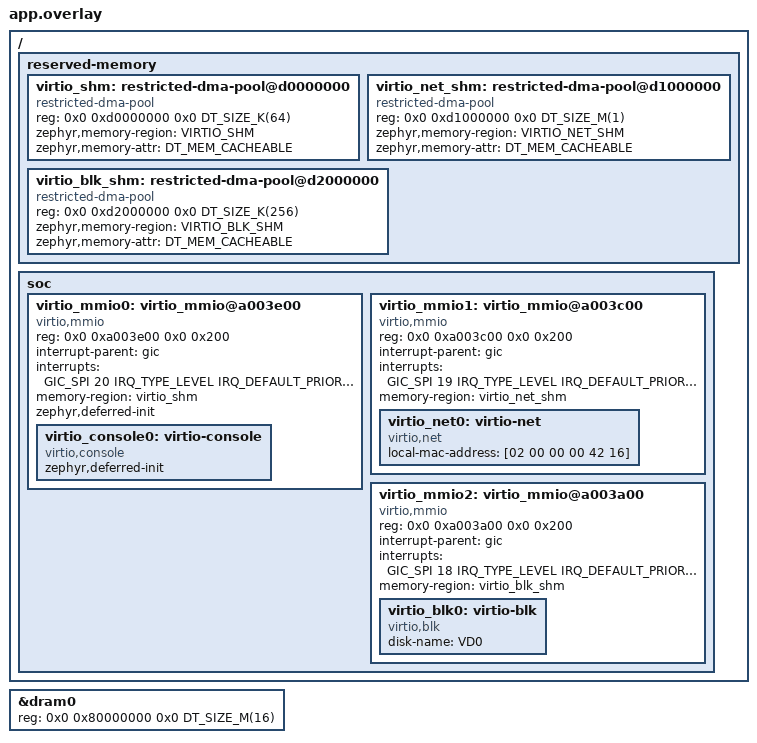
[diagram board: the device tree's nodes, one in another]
/*
 * SPDX-License-Identifier: Apache-2.0
 *
 * Memory layout and Remote I/O (VirtIO) device of the Zephyr VM, matching the
 * Bao configuration in configs/<platform>.c.
 */

#include <zephyr/dt-bindings/interrupt-controller/arm-gic.h>
#include <zephyr/dt-bindings/memory-attr/memory-attr.h>

/* Private VM memory: Zephyr's image and all of its RAM live here */
&dram0 {
	reg = <0x0 0x80000000 0x0 DT_SIZE_M(16)>;
};

/ {
	/*
	 * The only memory shared with the VirtIO backend VM, declared as
	 * restricted DMA pools: the VirtIO transport allocates the virtqueues
	 * of a device from its pool and bounces the driver buffers through
	 * it, so nothing else of Zephyr is visible to the backend. Bao shares
	 * one region per Remote I/O device, so each device has its own pool.
	 * The zephyr,memory-attr property is what gets a region mapped by the
	 * MMU.
	 */
	reserved-memory {
		#address-cells = <2>;
		#size-cells = <2>;
		ranges;

		virtio_shm: restricted-dma-pool@d0000000 {
			compatible = "restricted-dma-pool", "zephyr,memory-region";
			reg = <0x0 0xd0000000 0x0 DT_SIZE_K(64)>;
			zephyr,memory-region = "VIRTIO_SHM";
			zephyr,memory-attr = <DT_MEM_CACHEABLE>;
		};

		virtio_net_shm: restricted-dma-pool@d1000000 {
			compatible = "restricted-dma-pool", "zephyr,memory-region";
			reg = <0x0 0xd1000000 0x0 DT_SIZE_M(1)>;
			zephyr,memory-region = "VIRTIO_NET_SHM";
			zephyr,memory-attr = <DT_MEM_CACHEABLE>;
		};

		virtio_blk_shm: restricted-dma-pool@d2000000 {
			compatible = "restricted-dma-pool", "zephyr,memory-region";
			reg = <0x0 0xd2000000 0x0 DT_SIZE_K(256)>;
			zephyr,memory-region = "VIRTIO_BLK_SHM";
			zephyr,memory-attr = <DT_MEM_CACHEABLE>;
		};
	};

	soc {
		/*
		 * VirtIO MMIO device emulated by the backend. Accesses are
		 * forwarded by Bao to the backend, so the initialization is
		 * deferred until the application decides to wait for it. The
		 * interrupt (SPI 20, i.e. interrupt 52) is injected by Bao.
		 */
		virtio_mmio0: virtio_mmio@a003e00 {
			compatible = "virtio,mmio";
			reg = <0x0 0xa003e00 0x0 0x200>;
			interrupt-parent = <&gic>;
			interrupts = <GIC_SPI 20 IRQ_TYPE_LEVEL IRQ_DEFAULT_PRIORITY>;
			memory-region = <&virtio_shm>;
			zephyr,deferred-init;
			status = "okay";

			virtio_console0: virtio-console {
				compatible = "virtio,console";
				zephyr,deferred-init;
				status = "okay";
			};
		};

		/*
		 * VirtIO network device (SPI 19, i.e. interrupt 51). The
		 * network stack sets its interface up at boot, so this one is
		 * not deferred: Zephyr only boots once the backend is running.
		 */
		virtio_mmio1: virtio_mmio@a003c00 {
			compatible = "virtio,mmio";
			reg = <0x0 0xa003c00 0x0 0x200>;
			interrupt-parent = <&gic>;
			interrupts = <GIC_SPI 19 IRQ_TYPE_LEVEL IRQ_DEFAULT_PRIORITY>;
			memory-region = <&virtio_net_shm>;
			status = "okay";

			virtio_net0: virtio-net {
				compatible = "virtio,net";
				local-mac-address = [02 00 00 00 42 16];
				status = "okay";
			};
		};

		/*
		 * VirtIO block device (SPI 18, i.e. interrupt 50), also set
		 * up at boot.
		 */
		virtio_mmio2: virtio_mmio@a003a00 {
			compatible = "virtio,mmio";
			reg = <0x0 0xa003a00 0x0 0x200>;
			interrupt-parent = <&gic>;
			interrupts = <GIC_SPI 18 IRQ_TYPE_LEVEL IRQ_DEFAULT_PRIORITY>;
			memory-region = <&virtio_blk_shm>;
			status = "okay";

			virtio_blk0: virtio-blk {
				compatible = "virtio,blk";
				disk-name = "VD0";
				status = "okay";
			};
		};
	};
};
